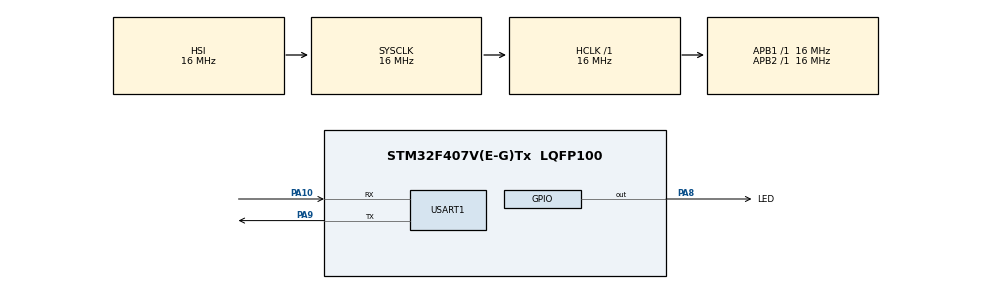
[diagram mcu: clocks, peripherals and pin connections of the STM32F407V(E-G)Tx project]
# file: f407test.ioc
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Mcu.Family=STM32F4
Mcu.Name=STM32F407V(E-G)Tx
Mcu.Package=LQFP100
NVIC.PriorityGroup=NVIC_PRIORITYGROUP_4
PA10.Mode=Asynchronous
PA10.Signal=USART1_RX
PA13.Mode=Serial_Wire
PA13.Signal=SYS_JTMS-SWDIO
PA14.Mode=Serial_Wire
PA14.Signal=SYS_JTCK-SWCLK
PA8.GPIO_Label=LED
PA8.Signal=GPIO_Output
PA9.Mode=Asynchronous
PA9.Signal=USART1_TX
PH0-OSC_IN.Mode=HSE-External-Oscillator
PH0-OSC_IN.Signal=RCC_OSC_IN
PH1-OSC_OUT.Mode=HSE-External-Oscillator
PH1-OSC_OUT.Signal=RCC_OSC_OUT
ProjectManager.HeapSize=0x200
ProjectManager.StackSize=0x400
ProjectManager.TargetToolchain=CMake
RCC.AHBFreq_Value=16000000
RCC.APB1Freq_Value=16000000
RCC.APB2Freq_Value=16000000
RCC.CortexFreq_Value=16000000
RCC.HSE_VALUE=8000000
RCC.HSI_VALUE=16000000
RCC.LSE_VALUE=32768
RCC.SYSCLKFreq_VALUE=16000000
RCC.VCOOutputFreq_Value=192000000
USART1.VirtualMode=VM_ASYNC
board=custom

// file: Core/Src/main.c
/* USER CODE BEGIN Header */
/**
  ******************************************************************************
  * @file           : main.c
  * @brief          : Main program body
  ******************************************************************************
  * @attention
  *
  * Copyright (c) 2026 STMicroelectronics.
  * All rights reserved.
  *
  * This software is licensed under terms that can be found in the LICENSE file
  * in the root directory of this software component.
  * If no LICENSE file comes with this software, it is provided AS-IS.
  *
  ******************************************************************************
  */
/* USER CODE END Header */
#include "main.h"

/* USER CODE BEGIN Includes */
#include "mrtk.h"
#include <stdio.h>

/* USER CODE END Includes */

UART_HandleTypeDef huart1;

void SystemClock_Config(void);
static void MX_GPIO_Init(void);
static void MX_USART1_UART_Init(void);

/* USER CODE BEGIN 0 */

int _write(int file, char *ptr, int len)
{
    // 把 ptr 指向的 len 个字节，通过 huart1 发送出去
    HAL_UART_Transmit(&huart1, (uint8_t *)ptr, len, HAL_MAX_DELAY);
    return len;
}

/* 三选一简单测试 */
/* 延时api使用 */
// #define DELAY_API_TEST 1
/* 相同优先级时间片轮转 */
// #define EQUAL_PRIO_TEST 1
/* 不同优先级高优先级优先抢占 */
#define EQUAL_PRIO_TEST 0

#if (DELAY_API_TEST == 1)

static void task1_entry(void *para) {
  while(1) {
    mrtk_schedule_lock();
    printf("task1 - tick cnt: %lu \r\n", g_mrtk_tick);
    mrtk_schedule_unlock();
    mrtk_task_delay(MRTK_SEC_TO_TICK(1));
  }
}

static void task2_entry(void *para) {
  while(1) {
    mrtk_schedule_lock();
    printf("task2 - tick cnt: %lu \r\n", g_mrtk_tick);
    mrtk_schedule_unlock();
    mrtk_task_delay(MRTK_SEC_TO_TICK(2));
  }
}

#else

static void task1_entry(void *para) {
  while(1) {
      /* 锁定调度器，防止 printf 被任务切换打断 */
      mrtk_schedule_lock();

      printf("task1 - tick cnt: %lu \r\n", g_mrtk_tick);

      /* 解锁调度器 */
      mrtk_schedule_unlock();
  }
}

static void task2_entry(void *para) {
  while(1) {
      /* 锁定调度器，防止 printf 被任务切换打断 */
      mrtk_schedule_lock();

      printf("task2 - tick cnt: %lu \r\n", g_mrtk_tick);

      /* 解锁调度器 */
      mrtk_schedule_unlock();
  }
}

#endif

/* USER CODE END 0 */

int main(void)
{

  /* MCU Configuration--------------------------------------------------------*/

  /* Reset of all peripherals, Initializes the Flash interface and the Systick. */
  HAL_Init();

  /* Configure the system clock */
  SystemClock_Config();

  /* Initialize all configured peripherals */
  MX_GPIO_Init();
  MX_USART1_UART_Init();
  /* USER CODE BEGIN 2 */

  mrtk_system_init();

#if (EQUAL_PRIO_TEST == 1)
  mrtk_task_t *task1 = mrtk_task_create("task1", task1_entry, MRTK_NULL, 512, 5, 10);
  mrtk_task_start(task1);
  mrtk_task_t *task2 = mrtk_task_create("task2", task2_entry, MRTK_NULL, 512, 5, 10);
  mrtk_task_start(task2);
#else
  mrtk_task_t *task1 = mrtk_task_create("task1", task1_entry, MRTK_NULL, 512, 4, 10);
  mrtk_task_start(task1);
  mrtk_task_t *task2 = mrtk_task_create("task2", task2_entry, MRTK_NULL, 512, 5, 10);
  mrtk_task_start(task2);
#endif

  mrtk_system_start();
  /* USER CODE END 2 */

  /* Infinite loop */
  while (1)
  {

  }
}

void SystemClock_Config(void)
{
  RCC_OscInitTypeDef RCC_OscInitStruct = {0};
  RCC_ClkInitTypeDef RCC_ClkInitStruct = {0};

  /** Configure the main internal regulator output voltage
  */
  __HAL_RCC_PWR_CLK_ENABLE();
  __HAL_PWR_VOLTAGESCALING_CONFIG(PWR_REGULATOR_VOLTAGE_SCALE1);

  /** Initializes the RCC Oscillators according to the specified parameters
  * in the RCC_OscInitTypeDef structure.
  */
  RCC_OscInitStruct.OscillatorType = RCC_OSCILLATORTYPE_HSI;
  RCC_OscInitStruct.HSIState = RCC_HSI_ON;
  RCC_OscInitStruct.HSICalibrationValue = RCC_HSICALIBRATION_DEFAULT;
  RCC_OscInitStruct.PLL.PLLState = RCC_PLL_NONE;
  if (HAL_RCC_OscConfig(&RCC_OscInitStruct) != HAL_OK)
  {
    Error_Handler();
  }

  /** Initializes the CPU, AHB and APB buses clocks
  */
  RCC_ClkInitStruct.ClockType = RCC_CLOCKTYPE_HCLK|RCC_CLOCKTYPE_SYSCLK
                              |RCC_CLOCKTYPE_PCLK1|RCC_CLOCKTYPE_PCLK2;
  RCC_ClkInitStruct.SYSCLKSource = RCC_SYSCLKSOURCE_HSI;
  RCC_ClkInitStruct.AHBCLKDivider = RCC_SYSCLK_DIV1;
  RCC_ClkInitStruct.APB1CLKDivider = RCC_HCLK_DIV1;
  RCC_ClkInitStruct.APB2CLKDivider = RCC_HCLK_DIV1;

  if (HAL_RCC_ClockConfig(&RCC_ClkInitStruct, FLASH_LATENCY_0) != HAL_OK)
  {
    Error_Handler();
  }
}

static void MX_USART1_UART_Init(void)
{

  huart1.Instance = USART1;
  huart1.Init.BaudRate = 115200;
  huart1.Init.WordLength = UART_WORDLENGTH_8B;
  huart1.Init.StopBits = UART_STOPBITS_1;
  huart1.Init.Parity = UART_PARITY_NONE;
  huart1.Init.Mode = UART_MODE_TX_RX;
  huart1.Init.HwFlowCtl = UART_HWCONTROL_NONE;
  huart1.Init.OverSampling = UART_OVERSAMPLING_16;
  if (HAL_UART_Init(&huart1) != HAL_OK)
  {
    Error_Handler();
  }

}

static void MX_GPIO_Init(void)
{
  GPIO_InitTypeDef GPIO_InitStruct = {0};

  /* GPIO Ports Clock Enable */
  __HAL_RCC_GPIOH_CLK_ENABLE();
  __HAL_RCC_GPIOA_CLK_ENABLE();

  /*Configure GPIO pin Output Level */
  HAL_GPIO_WritePin(LED_GPIO_Port, LED_Pin, GPIO_PIN_RESET);

  /*Configure GPIO pin : LED_Pin */
  GPIO_InitStruct.Pin = LED_Pin;
  GPIO_InitStruct.Mode = GPIO_MODE_OUTPUT_PP;
  GPIO_InitStruct.Pull = GPIO_NOPULL;
  GPIO_InitStruct.Speed = GPIO_SPEED_FREQ_LOW;
  HAL_GPIO_Init(LED_GPIO_Port, &GPIO_InitStruct);

}

void Error_Handler(void)
{
  __disable_irq();
  while (1)
  {
  }
}
